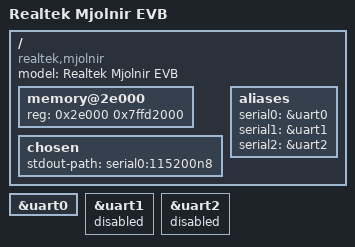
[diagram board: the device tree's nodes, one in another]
/dts-v1/;
#include "rtd1619.dtsi"
/ {
	compatible = "realtek,mjolnir", "realtek,rtd1619";
	model = "Realtek Mjolnir EVB";
	memory@2e000 {
		device_type = "memory";
		reg = <0x2e000 0x7ffd2000>;  
	};
	chosen {
		stdout-path = "serial0:115200n8";
	};
	aliases {
		serial0 = &uart0;
		serial1 = &uart1;
		serial2 = &uart2;
	};
};
&uart0 {
	status = "okay";
};
&uart1 {
	status = "disabled";
};
&uart2 {
	status = "disabled";
};
